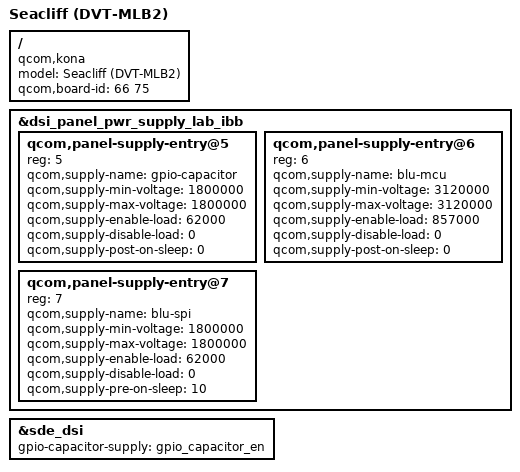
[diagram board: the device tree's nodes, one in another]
// SPDX-License-Identifier: GPL-2.0

/dts-v1/;
/plugin/;

#include "seacliff-dvt.dtsi"

/ {
	model = "Seacliff (DVT-MLB2)";
	compatible = "qcom,kona";
	qcom,board-id = <66 75>;
};

&dsi_panel_pwr_supply_lab_ibb {
	qcom,panel-supply-entry@5 {
		reg = <5>;
		qcom,supply-name = "gpio-capacitor";
		qcom,supply-min-voltage = <1800000>;
		qcom,supply-max-voltage = <1800000>;
		qcom,supply-enable-load = <62000>;
		qcom,supply-disable-load = <0>;
		qcom,supply-post-on-sleep = <0>;
	};

	qcom,panel-supply-entry@6 {
		reg = <6>;
		qcom,supply-name = "blu-mcu";
		qcom,supply-min-voltage = <3120000>;
		qcom,supply-max-voltage = <3120000>;
		qcom,supply-enable-load = <857000>;
		qcom,supply-disable-load = <0>;
		qcom,supply-post-on-sleep = <0>;
	};

	qcom,panel-supply-entry@7 {
		reg = <7>;
		qcom,supply-name = "blu-spi";
		qcom,supply-min-voltage = <1800000>;
		qcom,supply-max-voltage = <1800000>;
		qcom,supply-enable-load = <62000>;
		qcom,supply-disable-load = <0>;
		qcom,supply-pre-on-sleep = <10>;
	};
};

&sde_dsi {
	gpio-capacitor-supply = <&gpio_capacitor_en>;
};
